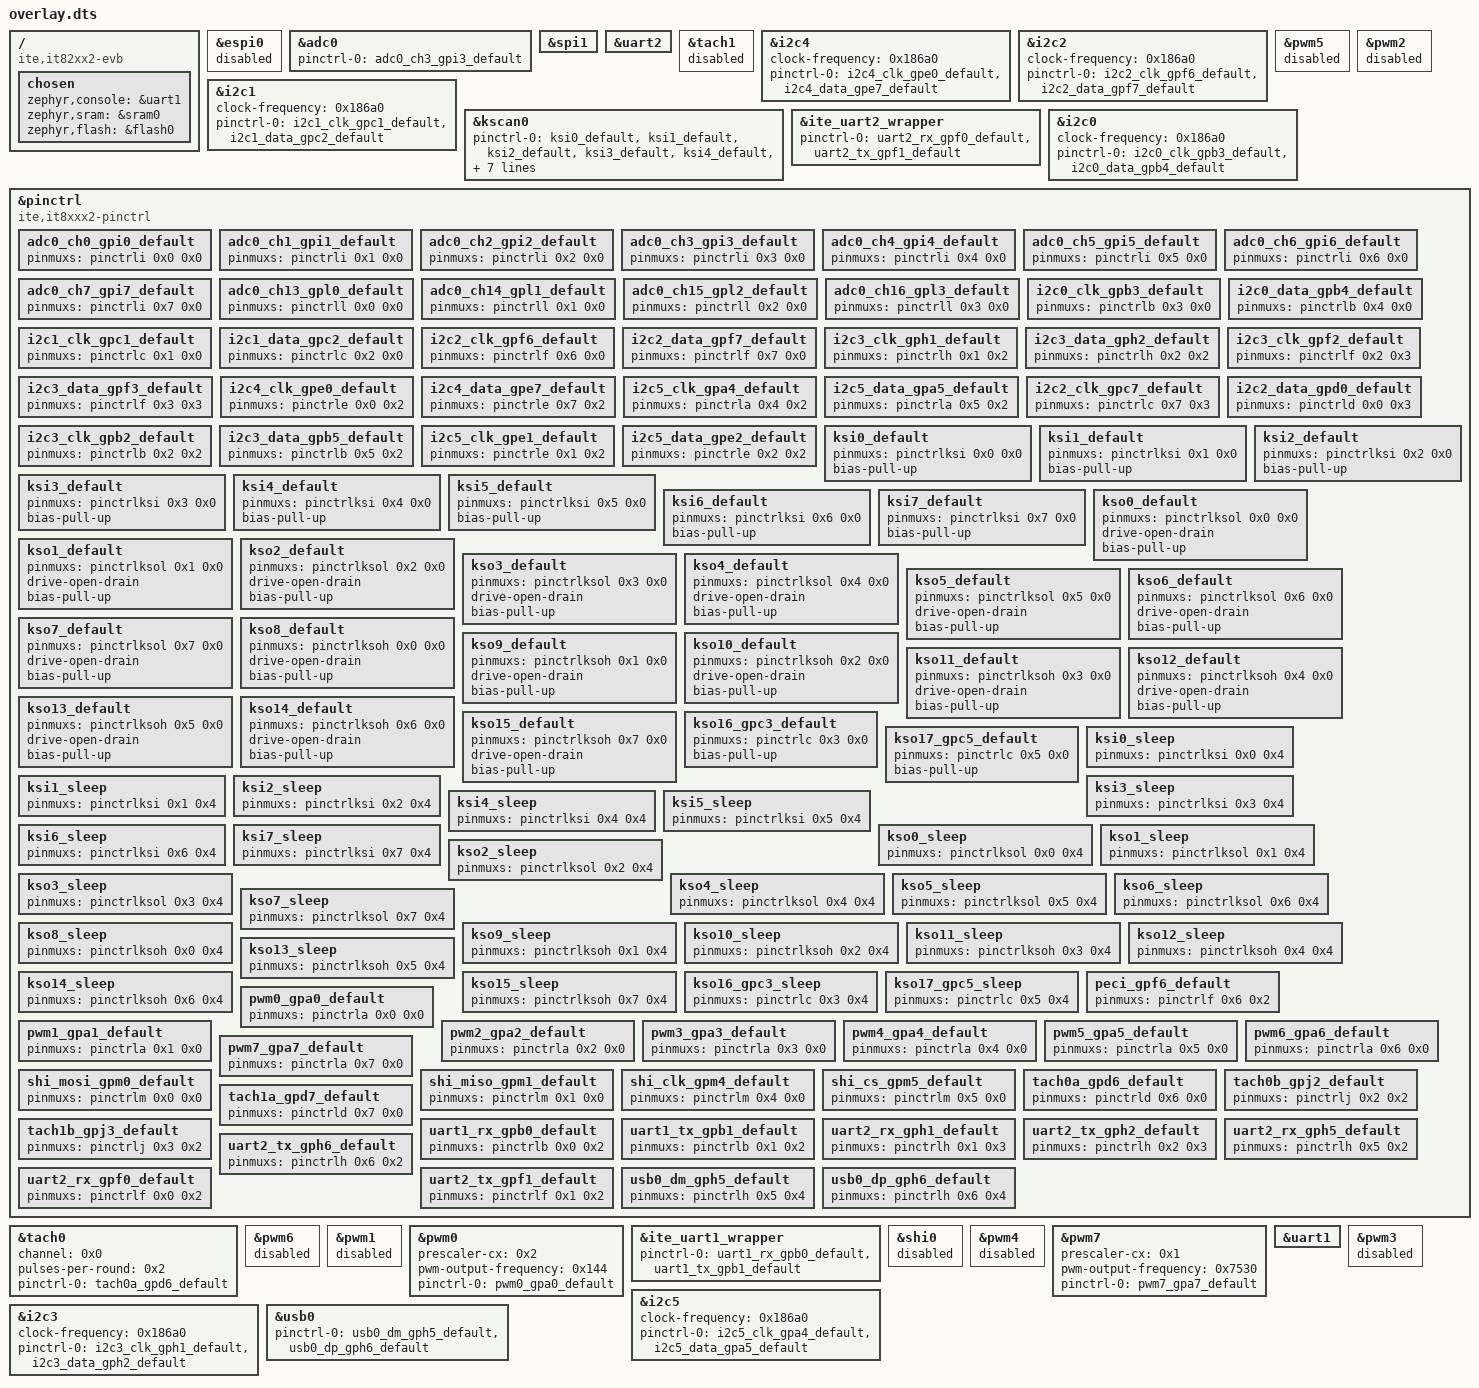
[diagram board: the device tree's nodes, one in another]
/ {
	compatible = "ite,it82xx2-evb";
	chosen {
		zephyr,console = &uart1;
		zephyr,sram = &sram0;
		zephyr,flash = &flash0;
	};
};
&espi0{
	status = "disabled";
};
&adc0{
	status = "okay";
	pinctrl-0 = < &adc0_ch3_gpi3_default >;
	pinctrl-names = "default";
};
&spi1{
	status = "okay";
};
&uart2{
	status = "okay";
};
&tach1{
	status = "disabled";
};
&i2c4{
	status = "okay";
	clock-frequency = < 0x186a0 >;
	pinctrl-0 = < &i2c4_clk_gpe0_default &i2c4_data_gpe7_default >;
	pinctrl-names = "default";
};
&i2c2{
	status = "okay";
	clock-frequency = < 0x186a0 >;
	pinctrl-0 = < &i2c2_clk_gpf6_default &i2c2_data_gpf7_default >;
	pinctrl-names = "default";
};
&i2c1{
	status = "okay";
	clock-frequency = < 0x186a0 >;
	pinctrl-0 = < &i2c1_clk_gpc1_default &i2c1_data_gpc2_default >;
	pinctrl-names = "default";
};
&kscan0{
	status = "okay";
	pinctrl-0 = < &ksi0_default &ksi1_default &ksi2_default &ksi3_default &ksi4_default &ksi5_default &ksi6_default &ksi7_default &kso0_default &kso1_default &kso2_default &kso3_default &kso4_default &kso5_default &kso6_default &kso7_default &kso8_default &kso9_default &kso10_default &kso11_default &kso12_default &kso13_default &kso14_default &kso15_default >;
	pinctrl-names = "default";
};
&pwm5{
	status = "disabled";
};
&pwm2{
	status = "disabled";
};
&ite_uart2_wrapper{
	status = "okay";
	pinctrl-0 = < &uart2_rx_gpf0_default &uart2_tx_gpf1_default >;
	pinctrl-names = "default";
};
&i2c0{
	status = "okay";
	clock-frequency = < 0x186a0 >;
	pinctrl-0 = < &i2c0_clk_gpb3_default &i2c0_data_gpb4_default >;
	pinctrl-names = "default";
};
&pinctrl{
	status = "okay";
};
&tach0{
	status = "okay";
	channel = < 0x0 >;
	pulses-per-round = < 0x2 >;
	pinctrl-0 = < &tach0a_gpd6_default >;
	pinctrl-names = "default";
};
&pwm6{
	status = "disabled";
};
&pwm1{
	status = "disabled";
};
&pwm0{
	status = "okay";
	prescaler-cx = < 0x2 >;
	pwm-output-frequency = < 0x144 >;
	pinctrl-0 = < &pwm0_gpa0_default >;
	pinctrl-names = "default";
};
&ite_uart1_wrapper{
	status = "okay";
	pinctrl-0 = < &uart1_rx_gpb0_default &uart1_tx_gpb1_default >;
	pinctrl-names = "default";
};
&shi0{
	status = "disabled";
};
&pwm4{
	status = "disabled";
};
&pwm7{
	status = "okay";
	prescaler-cx = < 0x1 >;
	pwm-output-frequency = < 0x7530 >;
	pinctrl-0 = < &pwm7_gpa7_default >;
	pinctrl-names = "default";
};
&uart1{
	status = "okay";
};
&i2c5{
	status = "okay";
	clock-frequency = < 0x186a0 >;
	pinctrl-0 = < &i2c5_clk_gpa4_default &i2c5_data_gpa5_default >;
	pinctrl-names = "default";
};
&pwm3{
	status = "disabled";
};
&i2c3{
	status = "okay";
	clock-frequency = < 0x186a0 >;
	pinctrl-0 = < &i2c3_clk_gph1_default &i2c3_data_gph2_default >;
	pinctrl-names = "default";
};
&usb0{
	status = "okay";
	pinctrl-0 = < &usb0_dm_gph5_default &usb0_dp_gph6_default >;
	pinctrl-names = "default";
};
&pinctrl{
	compatible = "ite,it8xxx2-pinctrl";
	#address-cells = < 0x1 >;
	#size-cells = < 0x1 >;
	status = "okay";
	adc0_ch0_gpi0_default: adc0_ch0_gpi0_default {
		pinmuxs = < &pinctrli 0x0 0x0 >;
	};
	adc0_ch1_gpi1_default: adc0_ch1_gpi1_default {
		pinmuxs = < &pinctrli 0x1 0x0 >;
	};
	adc0_ch2_gpi2_default: adc0_ch2_gpi2_default {
		pinmuxs = < &pinctrli 0x2 0x0 >;
	};
	adc0_ch3_gpi3_default: adc0_ch3_gpi3_default {
		pinmuxs = < &pinctrli 0x3 0x0 >;
	};
	adc0_ch4_gpi4_default: adc0_ch4_gpi4_default {
		pinmuxs = < &pinctrli 0x4 0x0 >;
	};
	adc0_ch5_gpi5_default: adc0_ch5_gpi5_default {
		pinmuxs = < &pinctrli 0x5 0x0 >;
	};
	adc0_ch6_gpi6_default: adc0_ch6_gpi6_default {
		pinmuxs = < &pinctrli 0x6 0x0 >;
	};
	adc0_ch7_gpi7_default: adc0_ch7_gpi7_default {
		pinmuxs = < &pinctrli 0x7 0x0 >;
	};
	adc0_ch13_gpl0_default: adc0_ch13_gpl0_default {
		pinmuxs = < &pinctrll 0x0 0x0 >;
	};
	adc0_ch14_gpl1_default: adc0_ch14_gpl1_default {
		pinmuxs = < &pinctrll 0x1 0x0 >;
	};
	adc0_ch15_gpl2_default: adc0_ch15_gpl2_default {
		pinmuxs = < &pinctrll 0x2 0x0 >;
	};
	adc0_ch16_gpl3_default: adc0_ch16_gpl3_default {
		pinmuxs = < &pinctrll 0x3 0x0 >;
	};
	i2c0_clk_gpb3_default: i2c0_clk_gpb3_default {
		pinmuxs = < &pinctrlb 0x3 0x0 >;
	};
	i2c0_data_gpb4_default: i2c0_data_gpb4_default {
		pinmuxs = < &pinctrlb 0x4 0x0 >;
	};
	i2c1_clk_gpc1_default: i2c1_clk_gpc1_default {
		pinmuxs = < &pinctrlc 0x1 0x0 >;
	};
	i2c1_data_gpc2_default: i2c1_data_gpc2_default {
		pinmuxs = < &pinctrlc 0x2 0x0 >;
	};
	i2c2_clk_gpf6_default: i2c2_clk_gpf6_default {
		pinmuxs = < &pinctrlf 0x6 0x0 >;
	};
	i2c2_data_gpf7_default: i2c2_data_gpf7_default {
		pinmuxs = < &pinctrlf 0x7 0x0 >;
	};
	i2c3_clk_gph1_default: i2c3_clk_gph1_default {
		pinmuxs = < &pinctrlh 0x1 0x2 >;
	};
	i2c3_data_gph2_default: i2c3_data_gph2_default {
		pinmuxs = < &pinctrlh 0x2 0x2 >;
	};
	i2c3_clk_gpf2_default: i2c3_clk_gpf2_default {
		pinmuxs = < &pinctrlf 0x2 0x3 >;
	};
	i2c3_data_gpf3_default: i2c3_data_gpf3_default {
		pinmuxs = < &pinctrlf 0x3 0x3 >;
	};
	i2c4_clk_gpe0_default: i2c4_clk_gpe0_default {
		pinmuxs = < &pinctrle 0x0 0x2 >;
	};
	i2c4_data_gpe7_default: i2c4_data_gpe7_default {
		pinmuxs = < &pinctrle 0x7 0x2 >;
	};
	i2c5_clk_gpa4_default: i2c5_clk_gpa4_default {
		pinmuxs = < &pinctrla 0x4 0x2 >;
	};
	i2c5_data_gpa5_default: i2c5_data_gpa5_default {
		pinmuxs = < &pinctrla 0x5 0x2 >;
	};
	i2c2_clk_gpc7_default: i2c2_clk_gpc7_default {
		pinmuxs = < &pinctrlc 0x7 0x3 >;
	};
	i2c2_data_gpd0_default: i2c2_data_gpd0_default {
		pinmuxs = < &pinctrld 0x0 0x3 >;
	};
	i2c3_clk_gpb2_default: i2c3_clk_gpb2_default {
		pinmuxs = < &pinctrlb 0x2 0x2 >;
	};
	i2c3_data_gpb5_default: i2c3_data_gpb5_default {
		pinmuxs = < &pinctrlb 0x5 0x2 >;
	};
	i2c5_clk_gpe1_default: i2c5_clk_gpe1_default {
		pinmuxs = < &pinctrle 0x1 0x2 >;
	};
	i2c5_data_gpe2_default: i2c5_data_gpe2_default {
		pinmuxs = < &pinctrle 0x2 0x2 >;
	};
	ksi0_default: ksi0_default {
		pinmuxs = < &pinctrlksi 0x0 0x0 >;
		bias-pull-up;
	};
	ksi1_default: ksi1_default {
		pinmuxs = < &pinctrlksi 0x1 0x0 >;
		bias-pull-up;
	};
	ksi2_default: ksi2_default {
		pinmuxs = < &pinctrlksi 0x2 0x0 >;
		bias-pull-up;
	};
	ksi3_default: ksi3_default {
		pinmuxs = < &pinctrlksi 0x3 0x0 >;
		bias-pull-up;
	};
	ksi4_default: ksi4_default {
		pinmuxs = < &pinctrlksi 0x4 0x0 >;
		bias-pull-up;
	};
	ksi5_default: ksi5_default {
		pinmuxs = < &pinctrlksi 0x5 0x0 >;
		bias-pull-up;
	};
	ksi6_default: ksi6_default {
		pinmuxs = < &pinctrlksi 0x6 0x0 >;
		bias-pull-up;
	};
	ksi7_default: ksi7_default {
		pinmuxs = < &pinctrlksi 0x7 0x0 >;
		bias-pull-up;
	};
	kso0_default: kso0_default {
		pinmuxs = < &pinctrlksol 0x0 0x0 >;
		drive-open-drain;
		bias-pull-up;
	};
	kso1_default: kso1_default {
		pinmuxs = < &pinctrlksol 0x1 0x0 >;
		drive-open-drain;
		bias-pull-up;
	};
	kso2_default: kso2_default {
		pinmuxs = < &pinctrlksol 0x2 0x0 >;
		drive-open-drain;
		bias-pull-up;
	};
	kso3_default: kso3_default {
		pinmuxs = < &pinctrlksol 0x3 0x0 >;
		drive-open-drain;
		bias-pull-up;
	};
	kso4_default: kso4_default {
		pinmuxs = < &pinctrlksol 0x4 0x0 >;
		drive-open-drain;
		bias-pull-up;
	};
	kso5_default: kso5_default {
		pinmuxs = < &pinctrlksol 0x5 0x0 >;
		drive-open-drain;
		bias-pull-up;
	};
	kso6_default: kso6_default {
		pinmuxs = < &pinctrlksol 0x6 0x0 >;
		drive-open-drain;
		bias-pull-up;
	};
	kso7_default: kso7_default {
		pinmuxs = < &pinctrlksol 0x7 0x0 >;
		drive-open-drain;
		bias-pull-up;
	};
	kso8_default: kso8_default {
		pinmuxs = < &pinctrlksoh 0x0 0x0 >;
		drive-open-drain;
		bias-pull-up;
	};
	kso9_default: kso9_default {
		pinmuxs = < &pinctrlksoh 0x1 0x0 >;
		drive-open-drain;
		bias-pull-up;
	};
	kso10_default: kso10_default {
		pinmuxs = < &pinctrlksoh 0x2 0x0 >;
		drive-open-drain;
		bias-pull-up;
	};
	kso11_default: kso11_default {
		pinmuxs = < &pinctrlksoh 0x3 0x0 >;
		drive-open-drain;
		bias-pull-up;
	};
	kso12_default: kso12_default {
		pinmuxs = < &pinctrlksoh 0x4 0x0 >;
		drive-open-drain;
		bias-pull-up;
	};
	kso13_default: kso13_default {
		pinmuxs = < &pinctrlksoh 0x5 0x0 >;
		drive-open-drain;
		bias-pull-up;
	};
	kso14_default: kso14_default {
		pinmuxs = < &pinctrlksoh 0x6 0x0 >;
		drive-open-drain;
		bias-pull-up;
	};
	kso15_default: kso15_default {
		pinmuxs = < &pinctrlksoh 0x7 0x0 >;
		drive-open-drain;
		bias-pull-up;
	};
	kso16_gpc3_default: kso16_gpc3_default {
		pinmuxs = < &pinctrlc 0x3 0x0 >;
		bias-pull-up;
	};
	kso17_gpc5_default: kso17_gpc5_default {
		pinmuxs = < &pinctrlc 0x5 0x0 >;
		bias-pull-up;
	};
	ksi0_sleep: ksi0_sleep {
		pinmuxs = < &pinctrlksi 0x0 0x4 >;
	};
	ksi1_sleep: ksi1_sleep {
		pinmuxs = < &pinctrlksi 0x1 0x4 >;
	};
	ksi2_sleep: ksi2_sleep {
		pinmuxs = < &pinctrlksi 0x2 0x4 >;
	};
	ksi3_sleep: ksi3_sleep {
		pinmuxs = < &pinctrlksi 0x3 0x4 >;
	};
	ksi4_sleep: ksi4_sleep {
		pinmuxs = < &pinctrlksi 0x4 0x4 >;
	};
	ksi5_sleep: ksi5_sleep {
		pinmuxs = < &pinctrlksi 0x5 0x4 >;
	};
	ksi6_sleep: ksi6_sleep {
		pinmuxs = < &pinctrlksi 0x6 0x4 >;
	};
	ksi7_sleep: ksi7_sleep {
		pinmuxs = < &pinctrlksi 0x7 0x4 >;
	};
	kso0_sleep: kso0_sleep {
		pinmuxs = < &pinctrlksol 0x0 0x4 >;
	};
	kso1_sleep: kso1_sleep {
		pinmuxs = < &pinctrlksol 0x1 0x4 >;
	};
	kso2_sleep: kso2_sleep {
		pinmuxs = < &pinctrlksol 0x2 0x4 >;
	};
	kso3_sleep: kso3_sleep {
		pinmuxs = < &pinctrlksol 0x3 0x4 >;
	};
	kso4_sleep: kso4_sleep {
		pinmuxs = < &pinctrlksol 0x4 0x4 >;
	};
	kso5_sleep: kso5_sleep {
		pinmuxs = < &pinctrlksol 0x5 0x4 >;
	};
	kso6_sleep: kso6_sleep {
		pinmuxs = < &pinctrlksol 0x6 0x4 >;
	};
	kso7_sleep: kso7_sleep {
		pinmuxs = < &pinctrlksol 0x7 0x4 >;
	};
	kso8_sleep: kso8_sleep {
		pinmuxs = < &pinctrlksoh 0x0 0x4 >;
	};
	kso9_sleep: kso9_sleep {
		pinmuxs = < &pinctrlksoh 0x1 0x4 >;
	};
	kso10_sleep: kso10_sleep {
		pinmuxs = < &pinctrlksoh 0x2 0x4 >;
	};
	kso11_sleep: kso11_sleep {
		pinmuxs = < &pinctrlksoh 0x3 0x4 >;
	};
	kso12_sleep: kso12_sleep {
		pinmuxs = < &pinctrlksoh 0x4 0x4 >;
	};
	kso13_sleep: kso13_sleep {
		pinmuxs = < &pinctrlksoh 0x5 0x4 >;
	};
	kso14_sleep: kso14_sleep {
		pinmuxs = < &pinctrlksoh 0x6 0x4 >;
	};
	kso15_sleep: kso15_sleep {
		pinmuxs = < &pinctrlksoh 0x7 0x4 >;
	};
	kso16_gpc3_sleep: kso16_gpc3_sleep {
		pinmuxs = < &pinctrlc 0x3 0x4 >;
	};
	kso17_gpc5_sleep: kso17_gpc5_sleep {
		pinmuxs = < &pinctrlc 0x5 0x4 >;
	};
	peci_gpf6_default: peci_gpf6_default {
		pinmuxs = < &pinctrlf 0x6 0x2 >;
	};
	pwm0_gpa0_default: pwm0_gpa0_default {
		pinmuxs = < &pinctrla 0x0 0x0 >;
	};
	pwm1_gpa1_default: pwm1_gpa1_default {
		pinmuxs = < &pinctrla 0x1 0x0 >;
	};
	pwm2_gpa2_default: pwm2_gpa2_default {
		pinmuxs = < &pinctrla 0x2 0x0 >;
	};
	pwm3_gpa3_default: pwm3_gpa3_default {
		pinmuxs = < &pinctrla 0x3 0x0 >;
	};
	pwm4_gpa4_default: pwm4_gpa4_default {
		pinmuxs = < &pinctrla 0x4 0x0 >;
	};
	pwm5_gpa5_default: pwm5_gpa5_default {
		pinmuxs = < &pinctrla 0x5 0x0 >;
	};
	pwm6_gpa6_default: pwm6_gpa6_default {
		pinmuxs = < &pinctrla 0x6 0x0 >;
	};
	pwm7_gpa7_default: pwm7_gpa7_default {
		pinmuxs = < &pinctrla 0x7 0x0 >;
	};
	shi_mosi_gpm0_default: shi_mosi_gpm0_default {
		pinmuxs = < &pinctrlm 0x0 0x0 >;
	};
	shi_miso_gpm1_default: shi_miso_gpm1_default {
		pinmuxs = < &pinctrlm 0x1 0x0 >;
	};
	shi_clk_gpm4_default: shi_clk_gpm4_default {
		pinmuxs = < &pinctrlm 0x4 0x0 >;
	};
	shi_cs_gpm5_default: shi_cs_gpm5_default {
		pinmuxs = < &pinctrlm 0x5 0x0 >;
	};
	tach0a_gpd6_default: tach0a_gpd6_default {
		pinmuxs = < &pinctrld 0x6 0x0 >;
	};
	tach0b_gpj2_default: tach0b_gpj2_default {
		pinmuxs = < &pinctrlj 0x2 0x2 >;
	};
	tach1a_gpd7_default: tach1a_gpd7_default {
		pinmuxs = < &pinctrld 0x7 0x0 >;
	};
	tach1b_gpj3_default: tach1b_gpj3_default {
		pinmuxs = < &pinctrlj 0x3 0x2 >;
	};
	uart1_rx_gpb0_default: uart1_rx_gpb0_default {
		pinmuxs = < &pinctrlb 0x0 0x2 >;
	};
	uart1_tx_gpb1_default: uart1_tx_gpb1_default {
		pinmuxs = < &pinctrlb 0x1 0x2 >;
	};
	uart2_rx_gph1_default: uart2_rx_gph1_default {
		pinmuxs = < &pinctrlh 0x1 0x3 >;
	};
	uart2_tx_gph2_default: uart2_tx_gph2_default {
		pinmuxs = < &pinctrlh 0x2 0x3 >;
	};
	uart2_rx_gph5_default: uart2_rx_gph5_default {
		pinmuxs = < &pinctrlh 0x5 0x2 >;
	};
	uart2_tx_gph6_default: uart2_tx_gph6_default {
		pinmuxs = < &pinctrlh 0x6 0x2 >;
	};
	uart2_rx_gpf0_default: uart2_rx_gpf0_default {
		pinmuxs = < &pinctrlf 0x0 0x2 >;
	};
	uart2_tx_gpf1_default: uart2_tx_gpf1_default {
		pinmuxs = < &pinctrlf 0x1 0x2 >;
	};
	usb0_dm_gph5_default: usb0_dm_gph5_default {
		pinmuxs = < &pinctrlh 0x5 0x4 >;
	};
	usb0_dp_gph6_default: usb0_dp_gph6_default {
		pinmuxs = < &pinctrlh 0x6 0x4 >;
	};
};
